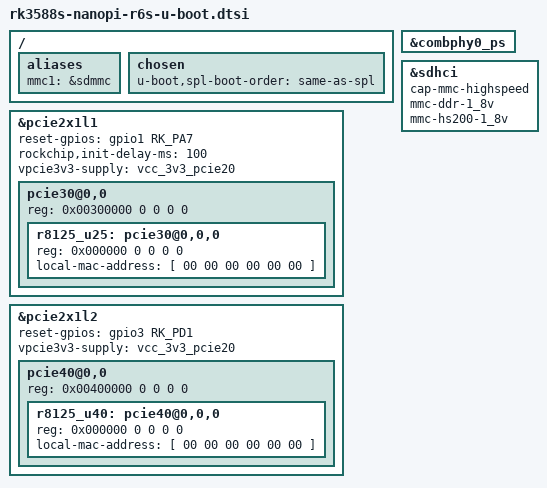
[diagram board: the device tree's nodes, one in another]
// SPDX-License-Identifier: (GPL-2.0+ OR MIT)
/*
 * Copyright (c) 2023 Collabora Ltd.
 */

#include "rk3588s-u-boot.dtsi"

/ {
	aliases {
		mmc1 = &sdmmc;
	};

	chosen {
		u-boot,spl-boot-order = "same-as-spl", &sdmmc, &sdhci;
	};
};

&combphy0_ps {
	status = "okay";
};

&pcie2x1l1 {
	reset-gpios = <&gpio1 RK_PA7 GPIO_ACTIVE_HIGH>;
	rockchip,init-delay-ms = <100>;
	vpcie3v3-supply = <&vcc_3v3_pcie20>;
	status = "okay";

	pcie30@0,0 {
		reg = <0x00300000 0 0 0 0>;
		#address-cells = <3>;
		#size-cells = <2>;

		r8125_u25: pcie30@0,0,0 {
			reg = <0x000000 0 0 0 0>;
			local-mac-address = [ 00 00 00 00 00 00 ];
		};
	};
};

&pcie2x1l2 {
	reset-gpios = <&gpio3 RK_PD1 GPIO_ACTIVE_HIGH>;
	vpcie3v3-supply = <&vcc_3v3_pcie20>;
	status = "okay";

	pcie40@0,0 {
		reg = <0x00400000 0 0 0 0>;
		#address-cells = <3>;
		#size-cells = <2>;

		r8125_u40: pcie40@0,0,0 {
			reg = <0x000000 0 0 0 0>;
			local-mac-address = [ 00 00 00 00 00 00 ];
		};
	};
};

&sdhci {
	cap-mmc-highspeed;
	mmc-ddr-1_8v;
	mmc-hs200-1_8v;
};
